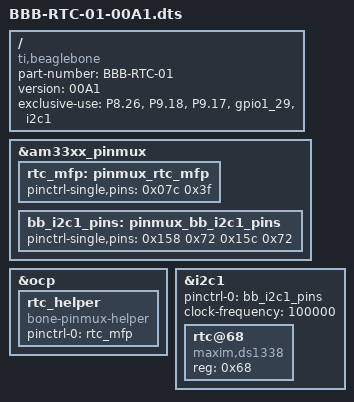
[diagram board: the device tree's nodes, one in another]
/*
 * Copyright (C) 2013 Hieu Duong <me@hieuduong.com>
 *
 * This program is free software; you can redistribute it and/or modify
 * it under the terms of the GNU General Public License version 2 as
 * published by the Free Software Foundation.
 * 
 */
/dts-v1/;
/plugin/;

/ {
	compatible = "ti,beaglebone", "ti,beaglebone-black";

	/* identification */
	part-number = "BBB-RTC-01";
	version = "00A1";
	
	/* state the resources this cape uses */
	exclusive-use =
		/* the pin header uses */
		"P8.26",	/* rtc:	gpio1_29 */
		"P9.18",	/* i2c1_sda */
		"P9.17",	/* i2c1_scl */
		/* the hardware ip uses */
		"gpio1_29", "i2c1";
		
	fragment@0 {
		target = <&am33xx_pinmux>;
		__overlay__ {
			rtc_mfp: pinmux_rtc_mfp {
				pinctrl-single,pins = <
					0x07c 0x3f	/* gpmc_csn0.gpio1_29, INPUT | PULLDIS | MODE 7 */
				>;
			};

			bb_i2c1_pins: pinmux_bb_i2c1_pins {
				pinctrl-single,pins = <
					0x158 0x72	/* spi0_d1.i2c1_sda, SLEWCTRL_SLOW | INPUT_PULLUP | MODE2 */
					0x15c 0x72	/* spi0_cs0.i2c1_scl, SLEWCTRL_SLOW | INPUT_PULLUP | MODE2 */
				>;
			};
		};
	};

	fragment@1 {
		target = <&ocp>;

		__overlay__ {
			rtc_helper {
				status = "okay";
				compatible = "bone-pinmux-helper";
				pinctrl-names = "default";
				pinctrl-0 = <&rtc_mfp>;
			};
		};
	};	
	
	fragment@2 {
		target = <&i2c1>;

		__overlay__ {
			status = "okay";
			pinctrl-names = "default";
			pinctrl-0 = <&bb_i2c1_pins>;
			
			/* this is the configuration part */
			clock-frequency = <100000>;	
			
			/* shut up DTC warnings */
			#address-cells = <1>;
			#size-cells = <0>;

			/* MCP79410 RTC module */
			rtc@68 {
				compatible = "maxim,ds1338";
				reg = <0x68>;
			};
		};
	};
};
		
		
